# WKUP_CTRL_MMR0_CFG0 register map
Vendor: Texas Instruments
Registers are 32-bit, read-write, reset 0x0 unless marked. A register's access mark holds for its fields unless they carry their own. Offsets are as the file gives them; [hi:lo] are bit positions; lines under a group give offsets from that group; {n}, {i} and the like mark numbered series.

## WKUP_CTRL_MMR0_CFG0 (part 4 of 11)
0x14300 CFG0_PM_PERMISSION ro — This register is writable only when LOCK0-KICK0:1 are unlocked
  [0] PM_PERMISSION_DEBUG_ACTIVE — Debug mode activatedTells PM-FW that it should not power-OFF supplies externally. The debugger being active should also cause the SMS hardware to override the external rail state during deeperSleep by forcing high the pmic_en output. In addition to forcing the rails of all SOC supplies on, this bit will also cause the VDD_CORE domain in SOCs with it, to get out of POR-reset and wake-up the Debugss so that its JTAG interface can connect. When this MMR bit is set, PM Hardware FSM should enter only into low power modes LPM0 to LPM1, but should not go into LPM2 to LPM4 where it clock-gates or power downs the clock sources.The debug_activated input set to '1' will also cause the M4 to get out of LPMs and exit WFI, since there is an interrupt allocated to that input port (debug_activated), after the attached debug is disconnected from the SOC the interrupt associated to debug_deactivated will be triggered by IceMelter and that should cause the M4 to exit the debug_activated interrupt service routine (ISR), and , if no other wake-up event is present then when debug_deactivated goes to '0' the PM-FW will do any required clearing/cleaning as part of the ISR set the M4 in WFI, and return to the low power state as defined in PMCTRL_SYS.LPM[2:0] bits. If instead of an attached debugger being present we have a software driven debug, then the interrupt that could be triggered instead of debug_activated will be debug_forceactive_int and causing same response as with debug_activated input/interrupt. In this case as part of the debug_activated ISR epilog the M4 will go back to WFI, , and return to the low power state as defined in PMCTRL_SYS.LPM[2:0] bits. 0 - Debug not activated 1 - Debug activated
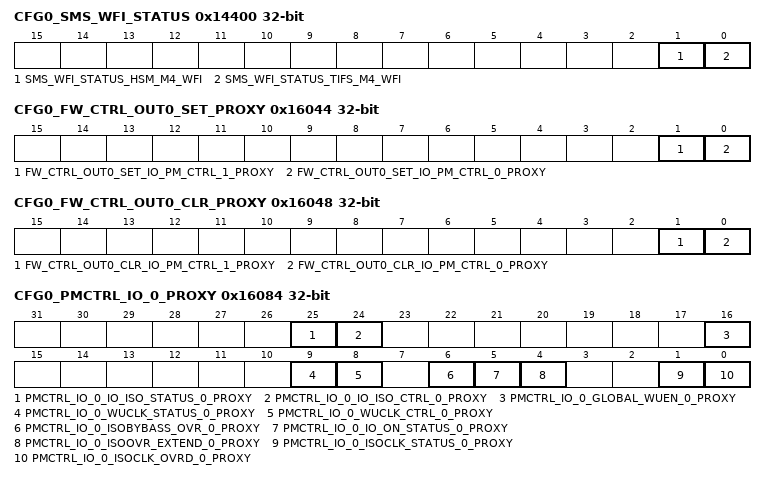
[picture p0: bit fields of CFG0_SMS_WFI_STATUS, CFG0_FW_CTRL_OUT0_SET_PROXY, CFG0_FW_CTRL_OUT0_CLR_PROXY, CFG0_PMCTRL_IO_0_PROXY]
0x14400 CFG0_SMS_WFI_STATUS ro — Provides WFI statue of SMS cores
  [1] SMS_WFI_STATUS_HSM_M4_WFI — Indicates WFI status of the HSM M4 processor in SMS 0 - Normal operation 1 - M4 is in WFI state
  [0] SMS_WFI_STATUS_TIFS_M4_WFI — Indicates WFI status of the TIFS M4 processor in SMS 0 - Normal operation 1 - M4 is in WFI state
{0x15100+4i} CFG0_CLAIMREG_P5_R{i}_READONLY ro (i=0..8)
  [31:0] CLAIMREG_P5_R{i}_READONLY — Claim bits for Partition 5
0x16040 CFG0_FW_CTRL_OUT0_PROXY ro — This register is writable only when LOCK0-KICK0:1 are unlocked
  [1:0] FW_CTRL_OUT0_IO_PM_CTRL_PROXY — This value is used by DMSC/SMS firmware to apply the DS (deep/deeper-sleep) values at once by qualifying the generation of the integration signal to the dsen_qualified to the IOs. These 2 bits are used in conjunction with those in the PMCTRL_IO_1/0 MMRs.The values gated/applied by dsen_qualified are those defined on the PADCONFIG MMR for each IO pad, as the DS selections, for the following IO pins:pupdsel, pi, txout, gz 0 - The active/normal mode pad-config defined values are applied to each IO/IO-pad that is part of the IO-PM daisy chain. 1 - The DS value, defined in the pad-config is applied to each IO/IO-pad that is part of the IO-PM daisy chain The io_pm_ctrl0 Is used to control deep/deeper-sleep values for the IOs in the WKUP section of the SOC. The io_pm_ctrl1 Is used to control deep/deeper-sleep values for the IOs in the MAIN section of the SOC.
0x16044 CFG0_FW_CTRL_OUT0_SET_PROXY access not given — This register is writable only when LOCK0-KICK0:1 are unlocked
  [1] FW_CTRL_OUT0_SET_IO_PM_CTRL_1_PROXY — This MMR bit is a W1ts bit field for MMR-bit-field FW_CTRL_OUT0.io_pm_ctrl1 (access R/W1TS)
  [0] FW_CTRL_OUT0_SET_IO_PM_CTRL_0_PROXY — This MMR bit is a W1ts bit field for MMR-bit-field FW_CTRL_OUT0.io_pm_ctrl0 (access R/W1TS)
0x16048 CFG0_FW_CTRL_OUT0_CLR_PROXY access not given — This register is writable only when LOCK0-KICK0:1 are unlocked
  [1] FW_CTRL_OUT0_CLR_IO_PM_CTRL_1_PROXY — This MMR bit is a W1ts bit field for MMR-bit-field FW_CTRL_OUT0.io_pm_ctrl1 (access R/W1TC)
  [0] FW_CTRL_OUT0_CLR_IO_PM_CTRL_0_PROXY — This MMR bit is a W1ts bit field for MMR-bit-field FW_CTRL_OUT0.io_pm_ctrl0 (access R/W1TC)
0x16080 CFG0_PMCTRL_SYS_PROXY reset 0x10 — This register is writable only when LOCK0-KICK0:1 are unlocked. Notice that this MMR includes a write-enable bit per field
  [4] PMCTRL_SYS_PMIC_EN_PROXY — PMIC enable. In order to write to this field, you need to write 1 in the same access to field pmic_en_we. NOTE: This MMR bit does not reflect any contribution from any debug related signal. 0 - Drives PMIC_EN output port to 0, unless there is an POWER-OFF inhibit condition due to Debug/Security 1 - Drives PMIC_EN output port to 1, if not already 1
0x16084 CFG0_PMCTRL_IO_0_PROXY access per field — Associated to the IO daisy chain of the safety_island IOs
  [25] PMCTRL_IO_0_IO_ISO_STATUS_0_PROXY ro — IO ISO Status 0 - IO isolation not active 1 - IO isolation active.Reflects value of SMS input port io_isoack coming back from IO pad ring
  [24] PMCTRL_IO_0_IO_ISO_CTRL_0_PROXY rw — IO ISO control. 0 - Turn off the IO isolation 1 - Turn on the IO isolation
  [16] PMCTRL_IO_0_GLOBAL_WUEN_0_PROXY rw — Global IO wakeup enable. This is a gating condition to all individual IO WUEN coming from control module. Gating is done in the Spinner logic. 0 - All individual IO WUEN are gated in the Spinner logic (override to 0). 1 - All individual IO WUEN from control module are going to IOs.Maps to SMS output port io_globalwkupen0 .
  [9] PMCTRL_IO_0_WUCLK_STATUS_0_PROXY ro — Reflects value of SMS input port io_wuclkack coming back from IO pad ring
  [8] PMCTRL_IO_0_WUCLK_CTRL_0_PROXY rw — Direct control on WUCLKIN signal to IO pad ring. 0 - WUCLKIN signal is driven to 0. IO wakeup daisy chain is functional as well as IO whose wakeup feature is enabled. 1 - WUCLKIN signal is driven to 1. IO wakeup daisy chain is reset and is latching current pad states and WUEN inputs
  [6] PMCTRL_IO_0_ISOBYBASS_OVR_0_PROXY rw — This MMR bit drives directly SMS output port io_isobypass0.
  [5] PMCTRL_IO_0_IO_ON_STATUS_0_PROXY ro — Gives the functional status of the IO ring. 0 - Part or all of the IOs are not in the ON state that is are in isolation state. 1 - All IOs are in the ON state. io_on_status = assign 1 if (io_iso == 0 & io_isoack==0 & io_iso_clk == 0 & io_isoclk_ack = 0 ) else 0;
  [4] PMCTRL_IO_0_ISOOVR_EXTEND_0_PROXY rw — Control for IO isolation extensionThis drives the SOC chain ISO-OVERRIDE global control.This bit drives directly the SMS output port io_isoovr0. At the SOC level it is used to enable when 1 or gate-off when 0, the individual ISOOR for each IO. This operates as a global enable/disable for the individual IOs. 0 - IO isolation is not extended. Transition happens as soon as automatic restore is completed. 1 - IO isolation is extended. The IOs whose ISOOVR bits have been individually set in their PADCFG MMRs will all get its IO isolation extended beyond the point when the initial IO daisy chain isolation is released.
  [1] PMCTRL_IO_0_ISOCLK_STATUS_0_PROXY ro — Reflects value of io_isoclkack coming back from IO pad ring.
  [0] PMCTRL_IO_0_ISOCLK_OVRD_0_PROXY rw — Override control on ISOCLKIN signal to IO pad ring.When not overridden this signal is controlled by hardware only. 0 - ISOCLKIN signal is not overriden. 1 - ISOCLKIN signal is overridden to active value (1).
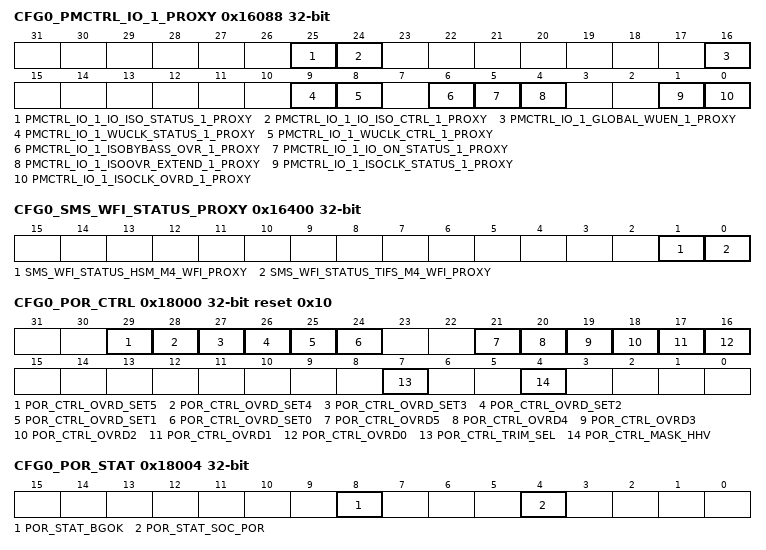
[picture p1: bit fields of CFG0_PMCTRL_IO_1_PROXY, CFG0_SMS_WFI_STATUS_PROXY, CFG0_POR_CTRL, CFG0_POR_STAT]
0x16088 CFG0_PMCTRL_IO_1_PROXY access per field — MMR is associated to the IO daisy chain of the IOs in the VD_CORE domain (main-SOC).
  [25] PMCTRL_IO_1_IO_ISO_STATUS_1_PROXY ro — IO ISO Status 0 - IO isolation not active 1 - IO isolation active.Reflects value of SMS input port io_isoack coming back from IO pad ring
  [24] PMCTRL_IO_1_IO_ISO_CTRL_1_PROXY rw — IO ISO control. 0 - Turn off the IO isolation 1 - Turn on the IO isolation
  [16] PMCTRL_IO_1_GLOBAL_WUEN_1_PROXY rw — Global IO wakeup enable. This is a gating condition to all individual IO WUEN coming from control module. Gating is done in the Spinner logic. 0 - All individual IO WUEN are gated in the Spinner logic (override to 0). 1 - All individual IO WUEN from control module are going to IOs.Maps to SMS output port io_globalwkupen1 .
  [9] PMCTRL_IO_1_WUCLK_STATUS_1_PROXY ro — Reflects value of SMS input port io_wuclkack coming back from IO pad ring
  [8] PMCTRL_IO_1_WUCLK_CTRL_1_PROXY rw — Direct control on WUCLKIN signal to IO pad ring. 0 - WUCLKIN signal is driven to 0. IO wakeup daisy chain is functional as well as IO whose wakeup feature is enabled. 1 - WUCLKIN signal is driven to 1. IO wakeup daisy chain is reset and is latching current pad states and WUEN inputs
  [6] PMCTRL_IO_1_ISOBYBASS_OVR_1_PROXY rw — This MMR bit drives directly SMS output port io_isobypass[0].
  [5] PMCTRL_IO_1_IO_ON_STATUS_1_PROXY ro — Gives the functional status of the IO ring. 0 - Part or all of the IOs are not in the ON state that is are in isolation state. 1 - All IOs are in the ON state. io_on_status = assign 1 if (io_iso == 0 & io_isoack==0 & io_iso_clk == 0 & io_isoclk_ack = 0 ) else 0;
  [4] PMCTRL_IO_1_ISOOVR_EXTEND_1_PROXY rw — Control for IO isolation extensionThis drives the SOC chain ISO-OVERRIDE global control.This bit drives directly the SMS output port io_isoovr[0]. At the SOC level it is used to enable when 1 or gate-off when 0, the individual ISOOR for each IO. This operates as a global enable/disable for the individual IOs. 0 - IO isolation is not extended. Transition happens as soon as automatic restore is completed. 1 - IO isolation is extended. The IOs whose ISOOVR bits have been individually set in their PADCFG MMRs will all get its IO isolation extended beyond the point when the initial IO daisy chain isolation is released.
  [1] PMCTRL_IO_1_ISOCLK_STATUS_1_PROXY ro — Reflects value of io_isoclkack coming back from IO pad ring.
  [0] PMCTRL_IO_1_ISOCLK_OVRD_1_PROXY rw — Override control on ISOCLKIN signal to IO pad ring.When not overridden this signal is controlled by hardware only. 0 - ISOCLKIN signal is not overriden. 1 - ISOCLKIN signal is overridden to active value (1).
0x16300 CFG0_PM_PERMISSION_PROXY ro — This register is writable only when LOCK0-KICK0:1 are unlocked
  [0] PM_PERMISSION_DEBUG_ACTIVE_PROXY — Debug mode activatedTells PM-FW that it should not power-OFF supplies externally. The debugger being active should also cause the SMS hardware to override the external rail state during deeperSleep by forcing high the pmic_en output. In addition to forcing the rails of all SOC supplies on, this bit will also cause the VDD_CORE domain in SOCs with it, to get out of POR-reset and wake-up the Debugss so that its JTAG interface can connect. When this MMR bit is set, PM Hardware FSM should enter only into low power modes LPM0 to LPM1, but should not go into LPM2 to LPM4 where it clock-gates or power downs the clock sources.The debug_activated input set to '1' will also cause the M4 to get out of LPMs and exit WFI, since there is an interrupt allocated to that input port (debug_activated), after the attached debug is disconnected from the SOC the interrupt associated to debug_deactivated will be triggered by IceMelter and that should cause the M4 to exit the debug_activated interrupt service routine (ISR), and , if no other wake-up event is present then when debug_deactivated goes to '0' the PM-FW will do any required clearing/cleaning as part of the ISR set the M4 in WFI, and return to the low power state as defined in PMCTRL_SYS.LPM[2:0] bits. If instead of an attached debugger being present we have a software driven debug, then the interrupt that could be triggered instead of debug_activated will be debug_forceactive_int and causing same response as with debug_activated input/interrupt. In this case as part of the debug_activated ISR epilog the M4 will go back to WFI, , and return to the low power state as defined in PMCTRL_SYS.LPM[2:0] bits. 0 - Debug not activated 1 - Debug activated
0x16400 CFG0_SMS_WFI_STATUS_PROXY ro — Provides WFI statue of SMS cores
  [1] SMS_WFI_STATUS_HSM_M4_WFI_PROXY — Indicates WFI status of the HSM M4 processor in SMS 0 - Normal operation 1 - M4 is in WFI state
  [0] SMS_WFI_STATUS_TIFS_M4_WFI_PROXY — Indicates WFI status of the TIFS M4 processor in SMS 0 - Normal operation 1 - M4 is in WFI state
{0x17100+4i} CFG0_CLAIMREG_P5_R{i} (i=0..8)
  [31:0] CLAIMREG_P5_R{i} — Claim bits for Partition 5
0x18000 CFG0_POR_CTRL reset 0x10 — Configures POR module reset behavior
  [29] POR_CTRL_OVRD_SET5 — Reserved override set
  [28] POR_CTRL_OVRD_SET4 — POKLVB override set
  [27] POR_CTRL_OVRD_SET3 — POKLVA override set
  [26] POR_CTRL_OVRD_SET2 — POKHV override set
  [25] POR_CTRL_OVRD_SET1 — BGOK override set
  [24] POR_CTRL_OVRD_SET0 — PORHV override set
  [21] POR_CTRL_OVRD5 — Reserved override enable
  [20] POR_CTRL_OVRD4 — POKLVB override enable
  [19] POR_CTRL_OVRD3 — POKLVA override enable
  [18] POR_CTRL_OVRD2 — POKHV override enable
  [17] POR_CTRL_OVRD1 — BGOK override enable
  [16] POR_CTRL_OVRD0 — PORHV override enable
  [7] POR_CTRL_TRIM_SEL — POR Trim Select 0 - Trim selections for Bandgap and POKs come from HHV defaults 1 - Trim selections for Bandgap and POKs come from POR_BANDGAP_CTRL and POR_POKxxx_CTRL registers
  [4] POR_CTRL_MASK_HHV — Mask HHV/SOC_PORz outputs when applying new trim values
0x18004 CFG0_POR_STAT ro — Shows POR module status
  [8] POR_STAT_BGOK — Bandgap OK status
  [4] POR_STAT_SOC_POR — POR module status 0 - Module is in functional mode 1 - Module is in reset mode
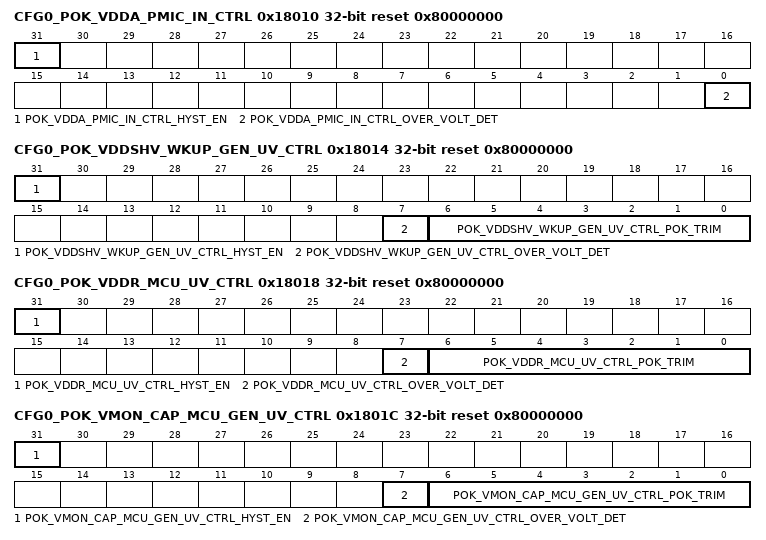
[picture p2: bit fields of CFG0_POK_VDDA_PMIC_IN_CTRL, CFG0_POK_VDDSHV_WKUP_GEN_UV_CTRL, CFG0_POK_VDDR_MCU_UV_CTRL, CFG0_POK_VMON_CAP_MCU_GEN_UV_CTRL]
0x18010 CFG0_POK_VDDA_PMIC_IN_CTRL reset 0x80000000 — Controls operation of the VDDA_PMIC_IN POK module
  [31] POK_VDDA_PMIC_IN_CTRL_HYST_EN — Enable POK hysteresis
  [0] POK_VDDA_PMIC_IN_CTRL_OVER_VOLT_DET — Over / under voltage detection mode 0 - Under voltage detection 1 - Over voltage detection
0x18014 CFG0_POK_VDDSHV_WKUP_GEN_UV_CTRL reset 0x80000000 — Controls operation of the VDDSHV_WKUP_GENERAL POK undervoltage detection
  [31] POK_VDDSHV_WKUP_GEN_UV_CTRL_HYST_EN — Enable POK hysteresis
  [7] POK_VDDSHV_WKUP_GEN_UV_CTRL_OVER_VOLT_DET — Over / under voltage detection mode 0 - Under voltage detection 1 - Over voltage detection
  [6:0] POK_VDDSHV_WKUP_GEN_UV_CTRL_POK_TRIM — POK trim bits. These bits are used to trim the comparator threshold voltage. See POK spec and J7 efuse spec for details
0x18018 CFG0_POK_VDDR_MCU_UV_CTRL reset 0x80000000 — Controls operation of the VDDR_MCU POK undervoltage detection
  [31] POK_VDDR_MCU_UV_CTRL_HYST_EN — Enable POK hysteresis
  [7] POK_VDDR_MCU_UV_CTRL_OVER_VOLT_DET — Over / under voltage detection mode 0 - Under voltage detection 1 - Over voltage detection
  [6:0] POK_VDDR_MCU_UV_CTRL_POK_TRIM — POK trim bits. These bits are used to trim the comparator threshold voltage. See POK spec and J7 efuse spec for details
0x1801C CFG0_POK_VMON_CAP_MCU_GEN_UV_CTRL reset 0x80000000 — Controls operation of the VMON_CAP_MCU_GENERAL POK undervoltage detection
  [31] POK_VMON_CAP_MCU_GEN_UV_CTRL_HYST_EN — Enable POK hysteresis
  [7] POK_VMON_CAP_MCU_GEN_UV_CTRL_OVER_VOLT_DET — Over / under voltage detection mode 0 - Under voltage detection 1 - Over voltage detection
  [6:0] POK_VMON_CAP_MCU_GEN_UV_CTRL_POK_TRIM — POK trim bits. These bits are used to trim the comparator threshold voltage. See POK spec and efuse spec for details
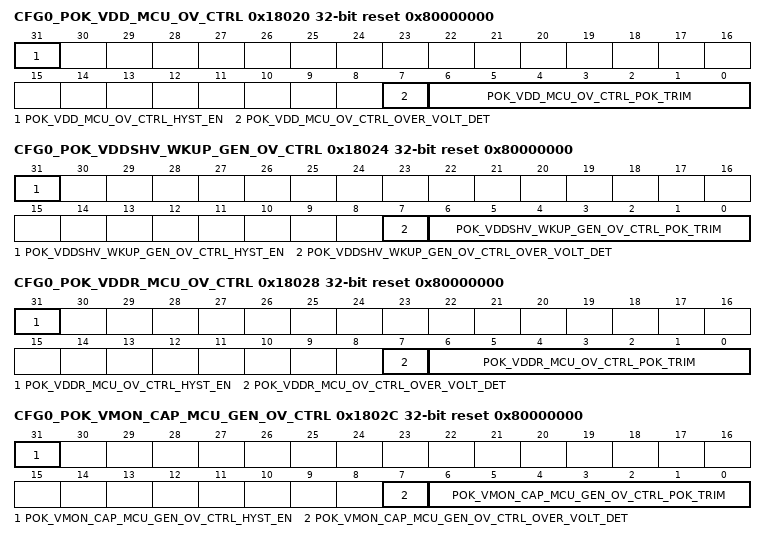
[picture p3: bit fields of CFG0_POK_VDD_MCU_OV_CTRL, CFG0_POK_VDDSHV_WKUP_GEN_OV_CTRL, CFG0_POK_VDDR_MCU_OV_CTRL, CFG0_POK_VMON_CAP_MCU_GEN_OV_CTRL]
0x18020 CFG0_POK_VDD_MCU_OV_CTRL reset 0x80000000 — Controls operation of the VDD_MCU overvoltage POK module
  [31] POK_VDD_MCU_OV_CTRL_HYST_EN — Enable POK hysteresis
  [7] POK_VDD_MCU_OV_CTRL_OVER_VOLT_DET — Over / under voltage detection mode 0 - Under voltage detection 1 - Over voltage detection
  [6:0] POK_VDD_MCU_OV_CTRL_POK_TRIM — POK trim bits. These bits are used to trim the comparator threshold voltage. See POK spec and J7 efuse spec for details
0x18024 CFG0_POK_VDDSHV_WKUP_GEN_OV_CTRL reset 0x80000000 — Controls operation of the VDDSHV_WKUP_GENERAL POK overvoltage detection
  [31] POK_VDDSHV_WKUP_GEN_OV_CTRL_HYST_EN — Enable POK hysteresis
  [7] POK_VDDSHV_WKUP_GEN_OV_CTRL_OVER_VOLT_DET — Over / under voltage detection mode 0 - Under voltage detection 1 - Over voltage detection
  [6:0] POK_VDDSHV_WKUP_GEN_OV_CTRL_POK_TRIM — POK trim bits. These bits are used to trim the comparator threshold voltage. See POK spec and J7 efuse spec for details
0x18028 CFG0_POK_VDDR_MCU_OV_CTRL reset 0x80000000 — Controls operation of the VDDR_MCU POK overvoltage detection
  [31] POK_VDDR_MCU_OV_CTRL_HYST_EN — Enable POK hysteresis
  [7] POK_VDDR_MCU_OV_CTRL_OVER_VOLT_DET — Over / under voltage detection mode 0 - Under voltage detection 1 - Over voltage detection
  [6:0] POK_VDDR_MCU_OV_CTRL_POK_TRIM — POK trim bits. These bits are used to trim the comparator threshold voltage. See POK spec and J7 efuse spec for details
0x1802C CFG0_POK_VMON_CAP_MCU_GEN_OV_CTRL reset 0x80000000 — Controls operation of the VMON_CAP_MCU_GENERAL POK overvoltage detection
  [31] POK_VMON_CAP_MCU_GEN_OV_CTRL_HYST_EN — Enable POK hysteresis
  [7] POK_VMON_CAP_MCU_GEN_OV_CTRL_OVER_VOLT_DET — Over / under voltage detection mode 0 - Under voltage detection 1 - Over voltage detection
  [6:0] POK_VMON_CAP_MCU_GEN_OV_CTRL_POK_TRIM — POK trim bits. These bits are used to trim the comparator threshold voltage. See POK spec and efuse spec for details
0x18070 CFG0_MAIN_VDOM_CTRL — Provides MAIN voltage domain isolation for deep sleep operation
  [0] MAIN_VDOM_CTRL_MAIN_VD_OFF — MAIN deep sleep isolation enable. This bit should be set prior to powering off the MAIN voltage domain to ensure proper signal isolation.
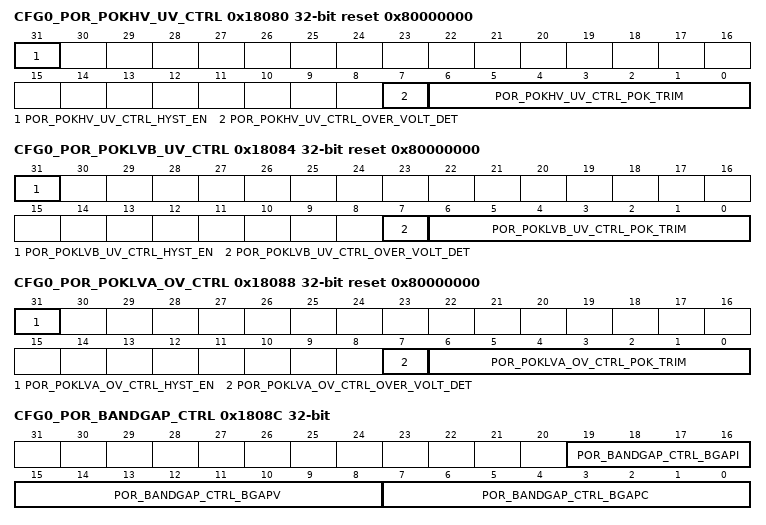
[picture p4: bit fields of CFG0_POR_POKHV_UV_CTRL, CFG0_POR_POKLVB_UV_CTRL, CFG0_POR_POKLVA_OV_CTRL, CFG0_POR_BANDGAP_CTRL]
0x18080 CFG0_POR_POKHV_UV_CTRL reset 0x80000000 — Controls operation of the 1.8V VDDA_MCU undervoltage POK within the POR
  [31] POR_POKHV_UV_CTRL_HYST_EN — Enable POK hysteresis
  [7] POR_POKHV_UV_CTRL_OVER_VOLT_DET — Over / under voltage detection mode 0 - Under voltage detection 1 - Over voltage detection
  [6:0] POR_POKHV_UV_CTRL_POK_TRIM — POK trim bits. These bits are used to trim the comparator threshold voltage. See POK spec and J7 efuse spec for details
0x18084 CFG0_POR_POKLVB_UV_CTRL reset 0x80000000 — Controls operation of the VDD_MCU undervoltage POK within the POR
  [31] POR_POKLVB_UV_CTRL_HYST_EN — Enable POK hysteresis
  [7] POR_POKLVB_UV_CTRL_OVER_VOLT_DET — Over / under voltage detection mode 0 - Under voltage detection 1 - Over voltage detection
  [6:0] POR_POKLVB_UV_CTRL_POK_TRIM — POK trim bits. These bits are used to trim the comparator threshold voltage. See POK spec and J7 efuse spec for details
0x18088 CFG0_POR_POKLVA_OV_CTRL reset 0x80000000 — Controls operation of the 1.8V VDDA_MCU overvoltage POK within the POR
  [31] POR_POKLVA_OV_CTRL_HYST_EN — Enable POK hysteresis
  [7] POR_POKLVA_OV_CTRL_OVER_VOLT_DET — Over / under voltage detection mode 0 - Under voltage detection 1 - Over voltage detection
  [6:0] POR_POKLVA_OV_CTRL_POK_TRIM — POK trim bits. These bits are used to trim the comparator threshold voltage. See POK spec and J7 efuse spec for details
0x1808C CFG0_POR_BANDGAP_CTRL — Controls the operation of the bandgap module within the POR
  [19:16] POR_BANDGAP_CTRL_BGAPI — Bandgap output current trim bits
  [15:8] POR_BANDGAP_CTRL_BGAPV — Bandgap output voltage magnitude trim bits
  [7:0] POR_BANDGAP_CTRL_BGAPC — Bandgap slope trim bits. Bit7 is used to calculate the offset
0x180A0 CFG0_TEMP_DIODE_TRIM — Trims the silicon junction temperature diode calculation
  [13:0] TEMP_DIODE_TRIM_TRIM — Sets the diode non-ideality factor (n), starting from 100th place decimal and going down
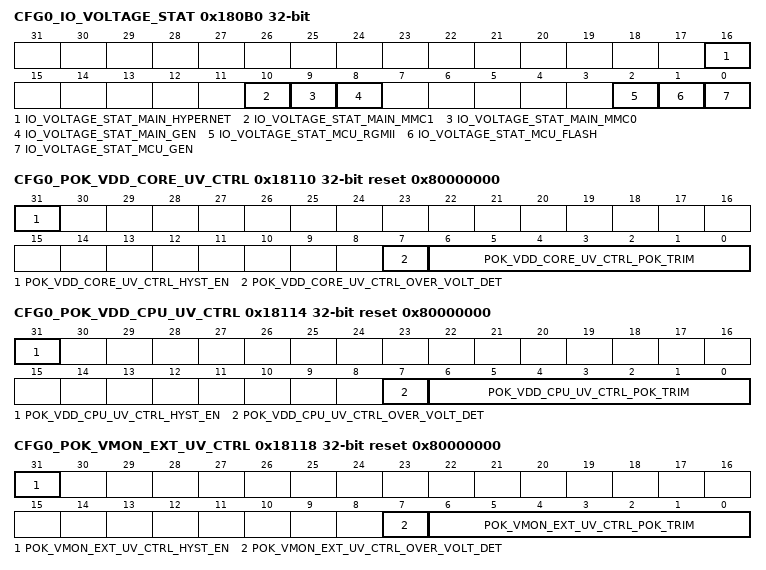
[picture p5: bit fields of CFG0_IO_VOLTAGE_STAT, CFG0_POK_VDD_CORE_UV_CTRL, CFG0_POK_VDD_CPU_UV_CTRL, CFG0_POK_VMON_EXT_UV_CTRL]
0x180B0 CFG0_IO_VOLTAGE_STAT ro — Indicates the I/O voltage of each LVCMOS dual I/O group
  [16] IO_VOLTAGE_STAT_MAIN_HYPERNET — Indicates the voltage for the HYPERNET I/O group 0 - I/O group is set for 3.3 V 1 - I/O group is set for 1.8 V
  [10] IO_VOLTAGE_STAT_MAIN_MMC1 — Indicates the voltage for the MMC1 I/O group 0 - I/O group is set for 3.3 V 1 - I/O group is set for 1.8 V
  [9] IO_VOLTAGE_STAT_MAIN_MMC0 — Indicates the voltage for the MMC0 I/O group 0 - I/O group is set for 3.3 V 1 - I/O group is set for 1.8 V
  [8] IO_VOLTAGE_STAT_MAIN_GEN — Indicates the voltage for the General I/O group 0 - I/O group is set for 3.3 V 1 - I/O group is set for 1.8 V
  [2] IO_VOLTAGE_STAT_MCU_RGMII — Indicates the voltage for the MCU CPSW2G RGMII I/O group 0 - I/O group is set for 3.3 V 1 - I/O group is set for 1.8 V
  [1] IO_VOLTAGE_STAT_MCU_FLASH — Indicates the voltage for the MCU Flash I/O group 0 - I/O group is set for 3.3 V 1 - I/O group is set for 1.8 V
  [0] IO_VOLTAGE_STAT_MCU_GEN — Indicates the voltage for the MCU General I/O group 0 - I/O group is set for 3.3 V 1 - I/O group is set for 1.8 V
0x18104 CFG0_MAIN_POR_TO_CTRL — Indicates the MAIN PORz timeout period
  [2:0] MAIN_POR_TO_CTRL_TIMEOUT_PER — MAIN PORz hardware timeout period.During normal operation, the assertion of a MAIN Domain PORz generates a reset request interrupt to the DMSC. The DMSC then performs steps to properly isolate the MAIN Domain before the actual reset is performed. A hardware timeout mechanism is provided to ensure that the PORz gets propagated to the MAIN Domain in the event that a error prevents the DMSC from completing the reset isolation. Field values (Others are reserved): 3'b000 - Immediate 3'b001 - 100 microsec 3'b010 - 200 microsec 3'b011 - 300 microsec 3'b100 - 400 microsec 3'b101 - 500 microsec
0x18110 CFG0_POK_VDD_CORE_UV_CTRL reset 0x80000000 — Controls operation of the VDD_CORE POK undervoltage detection
  [31] POK_VDD_CORE_UV_CTRL_HYST_EN — Enable POK hysteresis
  [7] POK_VDD_CORE_UV_CTRL_OVER_VOLT_DET — Over / under voltage detection mode 0 - Under voltage detection 1 - Over voltage detection
  [6:0] POK_VDD_CORE_UV_CTRL_POK_TRIM — POK trim bits. These bits are used to trim the comparator threshold voltage. See POK spec and efuse spec for details
0x18114 CFG0_POK_VDD_CPU_UV_CTRL reset 0x80000000 — Controls operation of the VDD_CPU POK undervoltage detection
  [31] POK_VDD_CPU_UV_CTRL_HYST_EN — Enable POK hysteresis
  [7] POK_VDD_CPU_UV_CTRL_OVER_VOLT_DET — Over / under voltage detection mode 0 - Under voltage detection 1 - Over voltage detection
  [6:0] POK_VDD_CPU_UV_CTRL_POK_TRIM — POK trim bits. These bits are used to trim the comparator threshold voltage. See POK spec and efuse spec for details
0x18118 CFG0_POK_VMON_EXT_UV_CTRL reset 0x80000000 — Controls operation of the VMON_EXTC POK undervoltage detection
  [31] POK_VMON_EXT_UV_CTRL_HYST_EN — Enable POK hysteresis
  [7] POK_VMON_EXT_UV_CTRL_OVER_VOLT_DET — Over / under voltage detection mode 0 - Under voltage detection 1 - Over voltage detection
  [6:0] POK_VMON_EXT_UV_CTRL_POK_TRIM — POK trim bits. These bits are used to trim the comparator threshold voltage. See POK spec and efuse spec for details
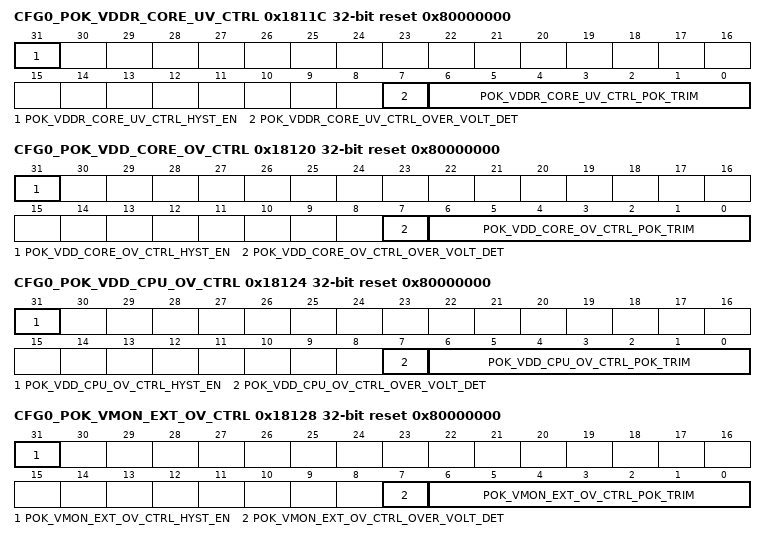
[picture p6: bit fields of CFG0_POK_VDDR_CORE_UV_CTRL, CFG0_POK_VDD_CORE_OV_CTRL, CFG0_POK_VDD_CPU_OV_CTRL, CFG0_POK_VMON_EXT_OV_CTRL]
0x1811C CFG0_POK_VDDR_CORE_UV_CTRL reset 0x80000000 — Controls operation of the VDDR_CORE POK undervoltage detection
  [31] POK_VDDR_CORE_UV_CTRL_HYST_EN — Enable POK hysteresis
  [7] POK_VDDR_CORE_UV_CTRL_OVER_VOLT_DET — Over / under voltage detection mode 0 - Under voltage detection 1 - Over voltage detection
  [6:0] POK_VDDR_CORE_UV_CTRL_POK_TRIM — POK trim bits. These bits are used to trim the comparator threshold voltage. See POK spec and efuse spec for details
0x18120 CFG0_POK_VDD_CORE_OV_CTRL reset 0x80000000 — Controls operation of the VDD_CORE POK overvoltage detection
  [31] POK_VDD_CORE_OV_CTRL_HYST_EN — Enable POK hysteresis
  [7] POK_VDD_CORE_OV_CTRL_OVER_VOLT_DET — Over / under voltage detection mode 0 - Under voltage detection 1 - Over voltage detection
  [6:0] POK_VDD_CORE_OV_CTRL_POK_TRIM — POK trim bits. These bits are used to trim the comparator threshold voltage. See POK spec and efuse spec for details
0x18124 CFG0_POK_VDD_CPU_OV_CTRL reset 0x80000000 — Controls operation of the VDD_CPU POK overvoltage detection
  [31] POK_VDD_CPU_OV_CTRL_HYST_EN — Enable POK hysteresis
  [7] POK_VDD_CPU_OV_CTRL_OVER_VOLT_DET — Over / under voltage detection mode 0 - Under voltage detection 1 - Over voltage detection
  [6:0] POK_VDD_CPU_OV_CTRL_POK_TRIM — POK trim bits. These bits are used to trim the comparator threshold voltage. See POK spec and efuse spec for details
0x18128 CFG0_POK_VMON_EXT_OV_CTRL reset 0x80000000 — Controls operation of the VMON_EXT POK overvoltage detection
  [31] POK_VMON_EXT_OV_CTRL_HYST_EN — Enable POK hysteresis
  [7] POK_VMON_EXT_OV_CTRL_OVER_VOLT_DET — Over / under voltage detection mode 0 - Under voltage detection 1 - Over voltage detection
  [6:0] POK_VMON_EXT_OV_CTRL_POK_TRIM — POK trim bits. These bits are used to trim the comparator threshold voltage. See POK spec and efuse spec for details
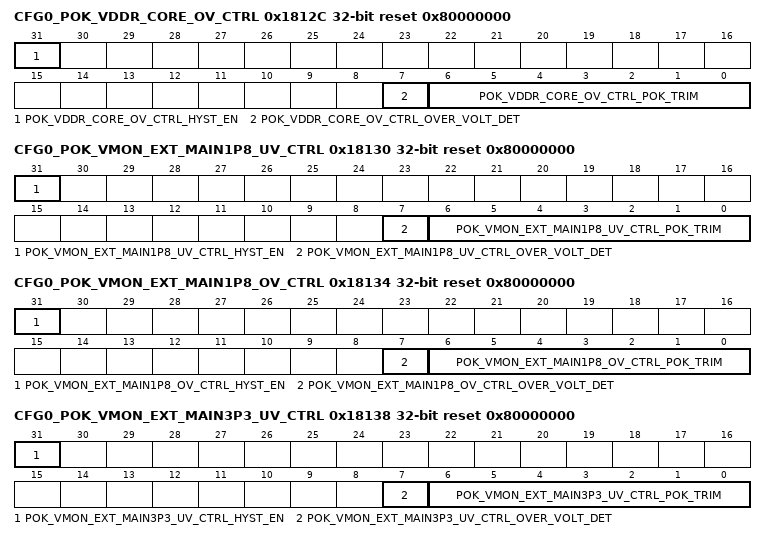
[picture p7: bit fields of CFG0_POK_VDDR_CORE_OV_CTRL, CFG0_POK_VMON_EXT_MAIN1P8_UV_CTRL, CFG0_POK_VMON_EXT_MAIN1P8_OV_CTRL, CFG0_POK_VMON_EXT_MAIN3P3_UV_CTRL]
0x1812C CFG0_POK_VDDR_CORE_OV_CTRL reset 0x80000000 — Controls operation of the VDDR_CORE POK overvoltage detection
  [31] POK_VDDR_CORE_OV_CTRL_HYST_EN — Enable POK hysteresis
  [7] POK_VDDR_CORE_OV_CTRL_OVER_VOLT_DET — Over / under voltage detection mode 0 - Under voltage detection 1 - Over voltage detection
  [6:0] POK_VDDR_CORE_OV_CTRL_POK_TRIM — POK trim bits. These bits are used to trim the comparator threshold voltage. See POK spec and efuse spec for details
0x18130 CFG0_POK_VMON_EXT_MAIN1P8_UV_CTRL reset 0x80000000 — Controls operation of the VMON_EXT_MAIN1P8 POK undervoltage detection
  [31] POK_VMON_EXT_MAIN1P8_UV_CTRL_HYST_EN — Enable POK hysteresis
  [7] POK_VMON_EXT_MAIN1P8_UV_CTRL_OVER_VOLT_DET — Over / under voltage detection mode 0 - Under voltage detection 1 - Over voltage detection
  [6:0] POK_VMON_EXT_MAIN1P8_UV_CTRL_POK_TRIM — POK trim bits. These bits are used to trim the comparator threshold voltage. See POK spec and efuse spec for details
0x18134 CFG0_POK_VMON_EXT_MAIN1P8_OV_CTRL reset 0x80000000 — Controls operation of the VMON_EXT_MAIN1P8 POK overvoltage detection
  [31] POK_VMON_EXT_MAIN1P8_OV_CTRL_HYST_EN — Enable POK hysteresis
  [7] POK_VMON_EXT_MAIN1P8_OV_CTRL_OVER_VOLT_DET — Over / under voltage detection mode 0 - Under voltage detection 1 - Over voltage detection
  [6:0] POK_VMON_EXT_MAIN1P8_OV_CTRL_POK_TRIM — POK trim bits. These bits are used to trim the comparator threshold voltage. See POK spec and efuse spec for details
0x18138 CFG0_POK_VMON_EXT_MAIN3P3_UV_CTRL reset 0x80000000 — Controls operation of the VMON_EXT_MAIN3P3 POK undervoltage detection
  [31] POK_VMON_EXT_MAIN3P3_UV_CTRL_HYST_EN — Enable POK hysteresis
  [7] POK_VMON_EXT_MAIN3P3_UV_CTRL_OVER_VOLT_DET — Over / under voltage detection mode 0 - Under voltage detection 1 - Over voltage detection
  [6:0] POK_VMON_EXT_MAIN3P3_UV_CTRL_POK_TRIM — POK trim bits. These bits are used to trim the comparator threshold voltage. See POK spec and efuse spec for details
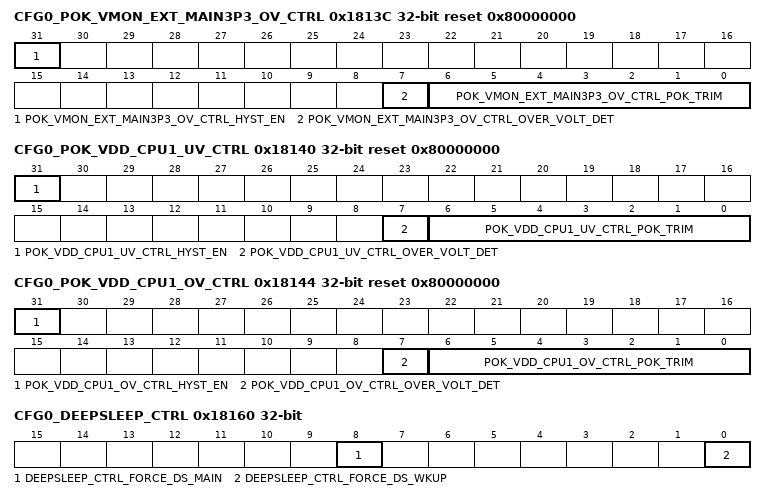
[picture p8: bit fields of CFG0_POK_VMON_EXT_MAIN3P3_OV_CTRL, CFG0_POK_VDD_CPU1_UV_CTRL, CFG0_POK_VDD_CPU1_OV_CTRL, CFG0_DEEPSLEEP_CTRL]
0x1813C CFG0_POK_VMON_EXT_MAIN3P3_OV_CTRL reset 0x80000000 — Controls operation of the VMON_EXT_MAIN3P3 POK overvoltage detection
  [31] POK_VMON_EXT_MAIN3P3_OV_CTRL_HYST_EN — Enable POK hysteresis
  [7] POK_VMON_EXT_MAIN3P3_OV_CTRL_OVER_VOLT_DET — Over / under voltage detection mode 0 - Under voltage detection 1 - Over voltage detection
  [6:0] POK_VMON_EXT_MAIN3P3_OV_CTRL_POK_TRIM — POK trim bits. These bits are used to trim the comparator threshold voltage. See POK spec and efuse spec for details
0x18140 CFG0_POK_VDD_CPU1_UV_CTRL reset 0x80000000 — Controls operation of the VDD_DDR0 POK undervoltage detection
  [31] POK_VDD_CPU1_UV_CTRL_HYST_EN — Enable POK hysteresis
  [7] POK_VDD_CPU1_UV_CTRL_OVER_VOLT_DET — Over / under voltage detection mode 0 - Under voltage detection 1 - Over voltage detection
  [6:0] POK_VDD_CPU1_UV_CTRL_POK_TRIM — POK trim bits. These bits are used to trim the comparator threshold voltage. See POK spec and efuse spec for details
0x18144 CFG0_POK_VDD_CPU1_OV_CTRL reset 0x80000000 — Controls operation of the VDD_DDR0 POK overvoltage detection
  [31] POK_VDD_CPU1_OV_CTRL_HYST_EN — Enable POK hysteresis
  [7] POK_VDD_CPU1_OV_CTRL_OVER_VOLT_DET — Over / under voltage detection mode 0 - Under voltage detection 1 - Over voltage detection
  [6:0] POK_VDD_CPU1_OV_CTRL_POK_TRIM — POK trim bits. These bits are used to trim the comparator threshold voltage. See POK spec and efuse spec for details
0x18160 CFG0_DEEPSLEEP_CTRL — Used to control IO deepsleep operation
  [8] DEEPSLEEP_CTRL_FORCE_DS_MAIN — Force all MAIN IOs into deepsleep mode when set
  [0] DEEPSLEEP_CTRL_FORCE_DS_WKUP — Force all WKUP IOs into deepsleep mode when set
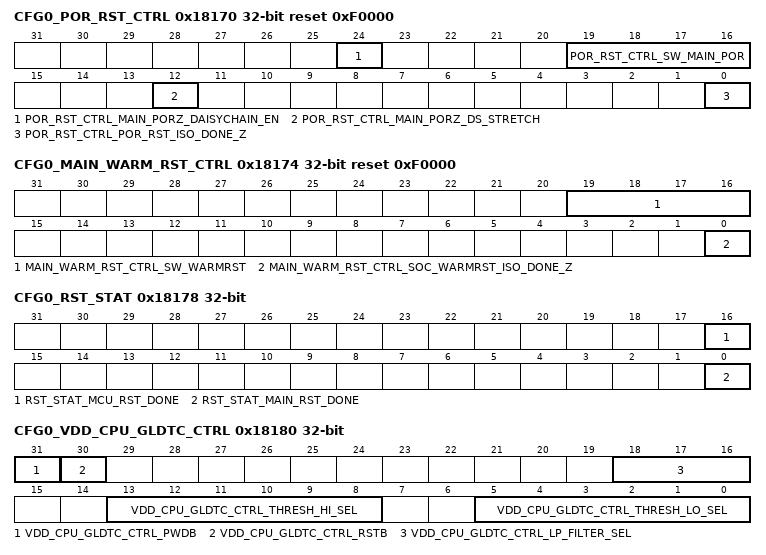
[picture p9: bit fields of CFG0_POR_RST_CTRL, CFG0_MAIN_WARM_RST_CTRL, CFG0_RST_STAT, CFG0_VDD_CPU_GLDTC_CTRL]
0x18170 CFG0_POR_RST_CTRL reset 0xF0000 — Controls MAIN domain power-on reset behavior.
  [24] POR_RST_CTRL_MAIN_PORZ_DAISYCHAIN_EN — MAIN PORz daisy-chain event enable.Determines if MAIN PORz reset events affect daisy-chain wakeup 0 - DeepSleep MAIN PORz event is not part of daisy-chain 1 - DeepSleep MAIN PORz event is combined w/ other daisy chain events.
  [19:16] POR_RST_CTRL_SW_MAIN_POR — Main Domain software power-on reset. When set to 4'b0110, a power-on is issued to the MAIN voltage domain. (Bits will reset to 4'b1111 on reset of the Main Domain)
  [12] POR_RST_CTRL_MAIN_PORZ_DS_STRETCH — DeepSleep mode MAIN PORz stretch. 0 - No stretching 1 - Stretch the Main PORz event captured during DeepSleep mode
  [0] POR_RST_CTRL_POR_RST_ISO_DONE_Z — Reset isolation completion (active low). This bit should be cleared only after reset isolation of the MAIN domain is complete. 0 - POR reset propagates to MAIN domain 1 - POR reset blocked from MAIN domain
0x18174 CFG0_MAIN_WARM_RST_CTRL reset 0xF0000 — Controls warm reset propagation to the MAIN domain. This allows the SMS to ensure that the MCU domain is properly isolated before the MAIN domain is reset.
  [19:16] MAIN_WARM_RST_CTRL_SW_WARMRST — Main Domain software warm reset. When set to 4'b0110, a warm reset is issued to the MAIN voltage domain. (Bits will reset to 4'b1111 on reset of the Main Domain)
  [0] MAIN_WARM_RST_CTRL_SOC_WARMRST_ISO_DONE_Z — Reset isolation completion (active low). This bit should be cleared only after reset isolation of the MAIN domain is complete. 0 - Warm reset propagates to MAIN domain 1 - Warm reset blocked from MAIN domain
0x18178 CFG0_RST_STAT ro — Shows the reset status
  [16] RST_STAT_MCU_RST_DONE — Indicates MCU domain reset status. 0 - MCU domain is in reset 1 - MCU domain reset is complete
  [0] RST_STAT_MAIN_RST_DONE — Indicates MAIN domain Warm reset status. 0 - MAIN domain is in Warm reset 1 - MAIN domain Warm reset is complete
0x1817C CFG0_MCU_WARM_RST_CTRL reset 0xF0000 — Controls warm reset propagation to the MCU domain. This allows the DMSC/SMS to ensure that the WKUP domain is properly isolated before the MCU domain is reset.
  [19:16] MCU_WARM_RST_CTRL_SW_WARMRST — Chip software warm reset. When set to 4'b0110, a warm reset is issued to the device (all voltage domains). (Bits will reset to 4'b1111 on reset completion.)
0x18180 CFG0_VDD_CPU_GLDTC_CTRL — Controls the voltage glitch detector circuit monitoring the VDD_CPU voltage domain
  [31] VDD_CPU_GLDTC_CTRL_PWDB — Power down - active low. 0 - Disable all functions 1 - Enable glitch detectors
  [30] VDD_CPU_GLDTC_CTRL_RSTB — Reset - active low. To ensure proper operation, rstb must be not be de-asserted for at least 100 ns after power-up (pwdb de-asserted). Additionally, rstb must be toggled low at least 200 ns after any change in threshold or low-pass filter settings to prevent abnormal trigger events. 0 - Reset glitch detector flags 1 - Glitch detection flags are enabled
  [18:16] VDD_CPU_GLDTC_CTRL_LP_FILTER_SEL — Selects the glitch detect low-pass filter bandwidth Field values (Others are reserved): 3'b000 - 150 kHz 3'b001 - 125 kHz 3'b010 - 100 kHz 3'b011 - 80 kHz 3'b100 - 60 kHz 3'b101 - 45 kHz 3'b110 - 30 kHz 3'b111 - 15 kHz
  [13:8] VDD_CPU_GLDTC_CTRL_THRESH_HI_SEL — Selects the high voltage glitch threshold as a percentage of the monitored voltage Field values (Others are reserved): 6'b000000 - 93.5% of VDD 6'b000001 - 94.0% of VDD 6'b000010 - 94.5% of VDD 6'b000011 - 95.0% of VDD 6'b000100 - 95.5% of VDD 6'b000101 - 96.0% of VDD 6'b000110 - 96.5% of VDD 6'b000111 - 97.0% of VDD 6'b001000 - 97.5% of VDD 6'b001001 - 98.0% of VDD 6'b001010 - 98.5% of VDD 6'b001011 - 99.0% of VDD 6'b001100 - 99.5% of VDD 6'b001101 - 100.0% of VDD 6'b001110 - 100.5% of VDD 6'b001111 - 101.0% of VDD 6'b010000 - 101.5% of VDD 6'b010001 - 102.0% of VDD 6'b010010 - 102.5% of VDD 6'b010011 - 103.0% of VDD 6'b010100 - 103.5% of VDD 6'b010101 - 104.0% of VDD 6'b010110 - 104.5% of VDD 6'b010111 - 105.0% of VDD 6'b011000 - 105.5% of VDD 6'b011001 - 106.0% of VDD 6'b011010 - 106.5% of VDD 6'b011011 - 107.0% of VDD 6'b011100 - 107.5% of VDD 6'b011101 - 108.0% of VDD 6'b011110 - 108.5% of VDD 6'b011111 - 109.0% of VDD 6'b100000 - 109.5% of VDD 6'b100001 - 110.0% of VDD 6'b100010 - 111.0% of VDD 6'b100011 - 112.0% of VDD 6'b100100 - 113.0% of VDD 6'b100101 - 114.0% of VDD 6'b100110 - 115.0% of VDD 6'b100111 - 116.0% of VDD 6'b101000 - 117.0% of VDD 6'b101001 - 118.0% of VDD 6'b101010 - 119.0% of VDD 6'b101011 - 120.0% of VDD 6'b101100 - 121.0% of VDD 6'b101101 - 122.0% of VDD 6'b101110 - 123.0% of VDD 6'b101111 - 124.0% of VDD 6'b110000 - 125.0% of VDD 6'b110001 - 126.0% of VDD 6'b110010 - 127.0% of VDD 6'b110011 - 128.0% of VDD 6'b110100 - 129.0% of VDD 6'b110101 - 130.0% of VDD 6'b110110 - 131.0% of VDD 6'b110111 - 132.0% of VDD 6'b111000 - 133.0% of VDD 6'b111001 - 134.0% of VDD 6'b111010 - 135.0% of VDD 6'b111011 - 136.0% of VDD 6'b111100 - 137.0% of VDD 6'b111101 - 138.0% of VDD 6'b111110 - 139.0% of VDD 6'b111111 - 140.0% of VDD
  [5:0] VDD_CPU_GLDTC_CTRL_THRESH_LO_SEL — Selects the low voltage glitch threshold as a percentage of the monitored voltage Field values (Others are reserved): 6'b000000 - 106.5% of VDD 6'b000001 - 106.0% of VDD 6'b000010 - 105.5% of VDD 6'b000011 - 105.0% of VDD 6'b000100 - 104.5% of VDD 6'b000101 - 104.0% of VDD 6'b000110 - 103.5% of VDD 6'b000111 - 103.0% of VDD 6'b001000 - 102.5% of VDD 6'b001001 - 102.0% of VDD 6'b001010 - 101.5% of VDD 6'b001011 - 101.0% of VDD 6'b001100 - 100.5% of VDD 6'b001101 - 100.0% of VDD 6'b001110 - 99.5% of VDD 6'b001111 - 99.0% of VDD 6'b010000 - 98.5% of VDD 6'b010001 - 98.0% of VDD 6'b010010 - 97.5% of VDD 6'b010011 - 97.0% of VDD 6'b010100 - 96.5% of VDD 6'b010101 - 96.0% of VDD 6'b010110 - 95.5% of VDD 6'b010111 - 95.0% of VDD 6'b011000 - 94.5% of VDD 6'b011001 - 94.0% of VDD 6'b011010 - 93.5% of VDD 6'b011011 - 93.0% of VDD 6'b011100 - 92.5% of VDD 6'b011101 - 92.0% of VDD 6'b011110 - 91.5% of VDD 6'b011111 - 91.0% of VDD 6'b100000 - 90.5% of VDD 6'b100001 - 90.0% of VDD 6'b100010 - 89.0% of VDD 6'b100011 - 88.0% of VDD 6'b100100 - 87.0% of VDD 6'b100101 - 86.0% of VDD 6'b100110 - 85.0% of VDD 6'b100111 - 84.0% of VDD 6'b101000 - 83.0% of VDD 6'b101001 - 82.0% of VDD 6'b101010 - 81.0% of VDD 6'b101011 - 80.0% of VDD 6'b101100 - 79.0% of VDD 6'b101101 - 78.0% of VDD 6'b101110 - 77.0% of VDD 6'b101111 - 76.0% of VDD 6'b110000 - 75.0% of VDD 6'b110001 - 74.0% of VDD 6'b110010 - 73.0% of VDD 6'b110011 - 72.0% of VDD 6'b110100 - 71.0% of VDD 6'b110101 - 70.0% of VDD 6'b110110 - 69.0% of VDD 6'b110111 - 68.0% of VDD 6'b111000 - 67.0% of VDD 6'b111001 - 66.0% of VDD 6'b111010 - 65.0% of VDD 6'b111011 - 64.0% of VDD 6'b111100 - 63.0% of VDD 6'b111101 - 62.0% of VDD 6'b111110 - 61.0% of VDD 6'b111111 - 60.0% of VDD
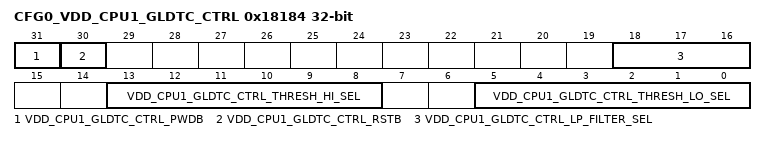
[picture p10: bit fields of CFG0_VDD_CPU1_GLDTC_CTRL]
0x18184 CFG0_VDD_CPU1_GLDTC_CTRL
  [31] VDD_CPU1_GLDTC_CTRL_PWDB — Power down - active low. 0 - Disable all functions 1 - Enable glitch detectors
  [30] VDD_CPU1_GLDTC_CTRL_RSTB — Reset - active low. To ensure proper operation, rstb must be not be de-asserted for at least 100 ns after power-up (pwdb de-asserted). Additionally, rstb must be toggled low at least 200 ns after any change in threshold or low-pass filter settings to prevent abnormal trigger events. 0 - Reset glitch detector flags 1 - Glitch detection flags are enabled
  [18:16] VDD_CPU1_GLDTC_CTRL_LP_FILTER_SEL — Selects the glitch detect low-pass filter bandwidth Field values (Others are reserved): 3'b000 - 150 kHz 3'b001 - 125 kHz 3'b010 - 100 kHz 3'b011 - 80 kHz 3'b100 - 60 kHz 3'b101 - 45 kHz 3'b110 - 30 kHz 3'b111 - 15 kHz
  [13:8] VDD_CPU1_GLDTC_CTRL_THRESH_HI_SEL — Selects the high voltage glitch threshold as a percentage of the monitored voltage Field values (Others are reserved): 6'b000000 - 93.5% of VDD 6'b000001 - 94.0% of VDD 6'b000010 - 94.5% of VDD 6'b000011 - 95.0% of VDD 6'b000100 - 95.5% of VDD 6'b000101 - 96.0% of VDD 6'b000110 - 96.5% of VDD 6'b000111 - 97.0% of VDD 6'b001000 - 97.5% of VDD 6'b001001 - 98.0% of VDD 6'b001010 - 98.5% of VDD 6'b001011 - 99.0% of VDD 6'b001100 - 99.5% of VDD 6'b001101 - 100.0% of VDD 6'b001110 - 100.5% of VDD 6'b001111 - 101.0% of VDD 6'b010000 - 101.5% of VDD 6'b010001 - 102.0% of VDD 6'b010010 - 102.5% of VDD 6'b010011 - 103.0% of VDD 6'b010100 - 103.5% of VDD 6'b010101 - 104.0% of VDD 6'b010110 - 104.5% of VDD 6'b010111 - 105.0% of VDD 6'b011000 - 105.5% of VDD 6'b011001 - 106.0% of VDD 6'b011010 - 106.5% of VDD 6'b011011 - 107.0% of VDD 6'b011100 - 107.5% of VDD 6'b011101 - 108.0% of VDD 6'b011110 - 108.5% of VDD 6'b011111 - 109.0% of VDD 6'b100000 - 109.5% of VDD 6'b100001 - 110.0% of VDD 6'b100010 - 111.0% of VDD 6'b100011 - 112.0% of VDD 6'b100100 - 113.0% of VDD 6'b100101 - 114.0% of VDD 6'b100110 - 115.0% of VDD 6'b100111 - 116.0% of VDD 6'b101000 - 117.0% of VDD 6'b101001 - 118.0% of VDD 6'b101010 - 119.0% of VDD 6'b101011 - 120.0% of VDD 6'b101100 - 121.0% of VDD 6'b101101 - 122.0% of VDD 6'b101110 - 123.0% of VDD 6'b101111 - 124.0% of VDD 6'b110000 - 125.0% of VDD 6'b110001 - 126.0% of VDD 6'b110010 - 127.0% of VDD 6'b110011 - 128.0% of VDD 6'b110100 - 129.0% of VDD 6'b110101 - 130.0% of VDD 6'b110110 - 131.0% of VDD 6'b110111 - 132.0% of VDD 6'b111000 - 133.0% of VDD 6'b111001 - 134.0% of VDD 6'b111010 - 135.0% of VDD 6'b111011 - 136.0% of VDD 6'b111100 - 137.0% of VDD 6'b111101 - 138.0% of VDD 6'b111110 - 139.0% of VDD 6'b111111 - 140.0% of VDD
  [5:0] VDD_CPU1_GLDTC_CTRL_THRESH_LO_SEL — Selects the low voltage glitch threshold as a percentage of the monitored voltage Field values (Others are reserved): 6'b000000 - 106.5% of VDD 6'b000001 - 106.0% of VDD 6'b000010 - 105.5% of VDD 6'b000011 - 105.0% of VDD 6'b000100 - 104.5% of VDD 6'b000101 - 104.0% of VDD 6'b000110 - 103.5% of VDD 6'b000111 - 103.0% of VDD 6'b001000 - 102.5% of VDD 6'b001001 - 102.0% of VDD 6'b001010 - 101.5% of VDD 6'b001011 - 101.0% of VDD 6'b001100 - 100.5% of VDD 6'b001101 - 100.0% of VDD 6'b001110 - 99.5% of VDD 6'b001111 - 99.0% of VDD 6'b010000 - 98.5% of VDD 6'b010001 - 98.0% of VDD 6'b010010 - 97.5% of VDD 6'b010011 - 97.0% of VDD 6'b010100 - 96.5% of VDD 6'b010101 - 96.0% of VDD 6'b010110 - 95.5% of VDD 6'b010111 - 95.0% of VDD 6'b011000 - 94.5% of VDD 6'b011001 - 94.0% of VDD 6'b011010 - 93.5% of VDD 6'b011011 - 93.0% of VDD 6'b011100 - 92.5% of VDD 6'b011101 - 92.0% of VDD 6'b011110 - 91.5% of VDD 6'b011111 - 91.0% of VDD 6'b100000 - 90.5% of VDD 6'b100001 - 90.0% of VDD 6'b100010 - 89.0% of VDD 6'b100011 - 88.0% of VDD 6'b100100 - 87.0% of VDD 6'b100101 - 86.0% of VDD 6'b100110 - 85.0% of VDD 6'b100111 - 84.0% of VDD 6'b101000 - 83.0% of VDD 6'b101001 - 82.0% of VDD 6'b101010 - 81.0% of VDD 6'b101011 - 80.0% of VDD 6'b101100 - 79.0% of VDD 6'b101101 - 78.0% of VDD 6'b101110 - 77.0% of VDD 6'b101111 - 76.0% of VDD 6'b110000 - 75.0% of VDD 6'b110001 - 74.0% of VDD 6'b110010 - 73.0% of VDD 6'b110011 - 72.0% of VDD 6'b110100 - 71.0% of VDD 6'b110101 - 70.0% of VDD 6'b110110 - 69.0% of VDD 6'b110111 - 68.0% of VDD 6'b111000 - 67.0% of VDD 6'b111001 - 66.0% of VDD 6'b111010 - 65.0% of VDD 6'b111011 - 64.0% of VDD 6'b111100 - 63.0% of VDD 6'b111101 - 62.0% of VDD 6'b111110 - 61.0% of VDD 6'b111111 - 60.0% of VDD
